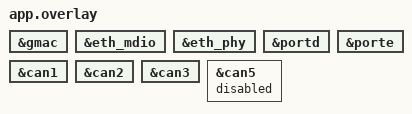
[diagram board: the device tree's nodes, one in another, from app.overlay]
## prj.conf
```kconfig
CONFIG_GPIO=y
CONFIG_PRINTK=y
CONFIG_LOG=y
CONFIG_MAIN_STACK_SIZE=3072

# --- CAN: Robstride motors are classic CAN 2.0B only -----------------------
CONFIG_CAN=y
CONFIG_CAN_FD_MODE=n

# --- Ethernet ----------------------------------------------------------------
# The Ethernet driver does no cache maintenance on packet buffers yet.
CONFIG_DCACHE=n

CONFIG_NETWORKING=y
CONFIG_NET_L2_ETHERNET=y
CONFIG_ETH_DRIVER=y
CONFIG_MDIO=y
CONFIG_NET_IPV4=y
CONFIG_NET_IPV6=n
CONFIG_NET_UDP=y
CONFIG_NET_TCP=n
CONFIG_NET_SOCKETS=y

# Board = 192.168.10.2, Jetson = 192.168.10.1 (udp_protocol/README.md)
CONFIG_NET_CONFIG_SETTINGS=y
CONFIG_NET_CONFIG_NEED_IPV4=y
CONFIG_NET_CONFIG_MY_IPV4_ADDR="192.168.10.2"
CONFIG_NET_CONFIG_MY_IPV4_NETMASK="255.255.255.0"
CONFIG_NET_CONFIG_PEER_IPV4_ADDR="192.168.10.1"
CONFIG_NET_CONFIG_INIT_TIMEOUT=0

# No TRNG driver for this chip in Zephyr yet (ports/IDs only; not crypto).
CONFIG_TEST_RANDOM_GENERATOR=y

# Bench diagnostics on the UART: "net iface", "net stats", "can show can0"
CONFIG_NET_STATISTICS=y
CONFIG_NET_STATISTICS_ETHERNET=y
CONFIG_SHELL=y
CONFIG_NET_SHELL=y
CONFIG_CAN_SHELL=y

CONFIG_NET_LOG=y
CONFIG_ETHERNET_LOG_LEVEL_INF=y
CONFIG_PHY_LOG_LEVEL_INF=y
```

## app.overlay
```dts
/* Gateway: Ethernet (MAC + MDIO + KSZ9031) and the four motor buses. */
#include "../boards/microchip/mega_can/mega_can-gmac.dtsi"

&gmac {
	status = "okay";
};

&eth_mdio {
	status = "okay";
};

&eth_phy {
	status = "okay";
};

&portd {
	status = "okay";
};

&porte {
	status = "okay";
};

/* motors: can0..can3 (classic 1 Mbit/s, from the board) */
&can1 {
	status = "okay";
};

&can2 {
	status = "okay";
};

&can3 {
	status = "okay";
};

/* can5 is only the bring-up loopback partner; not used here */
&can5 {
	status = "disabled";
};
```

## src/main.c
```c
/*
 * Copyright (c) 2026
 * SPDX-License-Identifier: Apache-2.0
 *
 * Mega-CAN gateway firmware: Jetson <-> UDP (protocol v3) <-> 4 Robstride motors.
 *
 * Same rules as udp_protocol/fake_board.py, which the software team codes
 * against:
 *   - one state packet back for every valid command, to the sender
 *   - 50 ms without a valid command -> all motors off, watchdog flag set
 *   - after that (and at boot) MODE_RUN is ignored until one all-OFF packet
 *   - packets with seq <= the last one used are dropped; a watchdog trip
 *     resets that, so a restarted Jetson program (seq back at 1) is accepted
 *   - bad packets set FLAG_BAD_PACKET in the next reply
 *
 * Foot sensors, ToF and power are reported as "no data" until their hardware
 * details are known.
 */

#include <string.h>

#include <zephyr/kernel.h>
#include <zephyr/drivers/gpio.h>
#include <zephyr/logging/log.h>
#include <zephyr/net/socket.h>

#include "motors.h"
#include "proto.h"

LOG_MODULE_REGISTER(gateway, LOG_LEVEL_INF);

#define WATCHDOG_MS       50
#define POLL_MS           5    /* watchdog check resolution */
#define FEEDBACK_WAIT_US  1500 /* a CAN command + reply takes ~0.3 ms */

static const struct gpio_dt_spec led = GPIO_DT_SPEC_GET(DT_ALIAS(led0), gpios);

static struct proto_command cmd;
static struct proto_state st;

static bool armed;
static uint32_t flags;
static uint32_t last_cmd_seq;
static int64_t last_cmd_ms; /* 0 = no command since boot */

static uint32_t now_us(void)
{
	return (uint32_t)k_ticks_to_us_floor64(k_uptime_ticks());
}

static bool header_ok(const struct proto_command *c)
{
	return memcmp(c->hdr.magic, PROTO_MAGIC, 4) == 0 && c->hdr.version == PROTO_VERSION &&
	       c->hdr.type == PROTO_TYPE_COMMAND && c->hdr.count == PROTO_NUM_MOTORS;
}

static bool all_off(const struct proto_command *c)
{
	for (int i = 0; i < PROTO_NUM_MOTORS; i++) {
		if (c->motor[i].mode != PROTO_MODE_OFF) {
			return false;
		}
	}
	return true;
}

static void trip_watchdog(void)
{
	if (armed) {
		LOG_WRN("watchdog: no command for %d ms, motors off", WATCHDOG_MS);
	}
	motors_all_off();
	armed = false;
	flags |= PROTO_FLAG_WATCHDOG_TRIPPED;
	last_cmd_seq = 0; /* accept a restarted client */
}

static void send_state(int sock, const struct sockaddr *to, socklen_t to_len)
{
	static uint32_t state_seq;

	memset(&st, 0, sizeof(st));
	memcpy(st.hdr.magic, PROTO_MAGIC, 4);
	st.hdr.version = PROTO_VERSION;
	st.hdr.type = PROTO_TYPE_STATE;
	st.hdr.count = PROTO_NUM_MOTORS;
	st.hdr.seq = ++state_seq;
	st.hdr.time_us = now_us();
	st.last_cmd_seq = last_cmd_seq;
	st.flags = flags;
	motors_fill_state(st.motor, st.bus);
	/* feet, tof, power: zeros = PROTO_SENSOR_NO_DATA until hardware is known */

	zsock_sendto(sock, &st, sizeof(st), 0, to, to_len);
}

int main(void)
{
	struct sockaddr_in addr = {
		.sin_family = AF_INET,
		.sin_port = htons(PROTO_PORT),
		.sin_addr.s_addr = htonl(INADDR_ANY),
	};
	int64_t last_blink = 0;
	int sock;

	gpio_pin_configure_dt(&led, GPIO_OUTPUT_INACTIVE);
	LOG_INF("Mega-CAN gateway, protocol v%d, UDP port %d", PROTO_VERSION, PROTO_PORT);

	motors_init();

	sock = zsock_socket(AF_INET, SOCK_DGRAM, IPPROTO_UDP);
	if (sock < 0 || zsock_bind(sock, (struct sockaddr *)&addr, sizeof(addr)) < 0) {
		LOG_ERR("UDP socket setup failed: %d", errno);
		return 0;
	}

	while (1) {
		struct zsock_pollfd pfd = {.fd = sock, .events = ZSOCK_POLLIN};
		struct sockaddr_in from;
		socklen_t from_len = sizeof(from);
		int64_t now;
		int len;

		zsock_poll(&pfd, 1, POLL_MS);
		now = k_uptime_get();

		/* LED: slow blink disarmed, fast blink armed */
		if (now - last_blink >= (armed ? 100 : 500)) {
			gpio_pin_toggle_dt(&led);
			last_blink = now;
		}

		if (last_cmd_ms != 0 && now - last_cmd_ms > WATCHDOG_MS &&
		    !(flags & PROTO_FLAG_WATCHDOG_TRIPPED)) {
			trip_watchdog();
		}

		if (!(pfd.revents & ZSOCK_POLLIN)) {
			continue;
		}
		len = zsock_recvfrom(sock, &cmd, sizeof(cmd), ZSOCK_MSG_DONTWAIT,
				     (struct sockaddr *)&from, &from_len);
		if (len < 0) {
			continue;
		}
		if (len != sizeof(cmd) || !header_ok(&cmd)) {
			flags |= PROTO_FLAG_BAD_PACKET;
			continue;
		}
		if (last_cmd_seq != 0 && cmd.hdr.seq <= last_cmd_seq) {
			continue; /* old or duplicate */
		}

		last_cmd_seq = cmd.hdr.seq;
		last_cmd_ms = now;
		if (all_off(&cmd)) {
			if (!armed) {
				LOG_INF("armed (all-off packet received)");
			}
			armed = true;
			flags &= ~PROTO_FLAG_WATCHDOG_TRIPPED;
		}

		motors_apply(cmd.motor, armed);
		motors_wait_feedback(K_USEC(FEEDBACK_WAIT_US));
		send_state(sock, (struct sockaddr *)&from, from_len);
		flags &= ~PROTO_FLAG_BAD_PACKET;
	}
	return 0;
}
```

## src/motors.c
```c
/*
 * Copyright (c) 2026
 * SPDX-License-Identifier: Apache-2.0
 *
 * Robstride motors on can0..can3. See motors.h.
 *
 * Frame per motor per tick (Robstride answers each with type 2 feedback):
 *   OFF       -> stop (type 4). Keeps feedback flowing while off.
 *   RUN       -> first tick: enable (type 3); after that: control (type 1)
 *   SET_ZERO  -> stop until the motor reports it is not running, then one
 *                set-zero (type 6). Never zeroes a running motor: with
 *                position gains active, moving the zero makes it jump.
 */

#include "motors.h"

#include <string.h>

#include <zephyr/device.h>
#include <zephyr/drivers/can.h>
#include <zephyr/logging/log.h>

#include "robstride.h"

LOG_MODULE_REGISTER(motors, LOG_LEVEL_INF);

#define HOST_ID            RS_DEFAULT_HOST_ID
#define MOTOR_CAN_TIMEOUT  100U /* ms: motor resets itself if CAN goes quiet */
#define FEEDBACK_STALE_MS  50
#define INIT_REPLY_TIMEOUT K_MSEC(20)

struct motor {
	const struct device *dev;
	uint8_t bus;
	uint8_t can_id;
	/* tick state (main thread only) */
	bool enabled;
	bool zeroed;
	/* feedback (written in the CAN RX callback) */
	struct rs_feedback fb;
	int64_t fb_time_ms; /* 0 = never */
};

/* Motor i on can<i>, factory ID 0x7F (IDs never changed, per Joa 2026-09-28). */
static struct motor motors[PROTO_NUM_MOTORS] = {
	{.dev = DEVICE_DT_GET(DT_NODELABEL(can0)), .bus = 0, .can_id = RS_DEFAULT_MOTOR_ID},
	{.dev = DEVICE_DT_GET(DT_NODELABEL(can1)), .bus = 1, .can_id = RS_DEFAULT_MOTOR_ID},
	{.dev = DEVICE_DT_GET(DT_NODELABEL(can2)), .bus = 2, .can_id = RS_DEFAULT_MOTOR_ID},
	{.dev = DEVICE_DT_GET(DT_NODELABEL(can3)), .bus = 3, .can_id = RS_DEFAULT_MOTOR_ID},
};

/* Bus health for all six controllers (unused ones report zeros). */
static const struct device *const bus_devs[PROTO_NUM_BUSES] = {
	DEVICE_DT_GET(DT_NODELABEL(can0)), DEVICE_DT_GET(DT_NODELABEL(can1)),
	DEVICE_DT_GET(DT_NODELABEL(can2)), DEVICE_DT_GET(DT_NODELABEL(can3)),
	NULL, NULL,
};

static struct k_spinlock fb_lock;
static atomic_t replied;  /* bit i = motor i answered this tick */
static uint32_t expected; /* bits of motors sent to this tick */
static K_SEM_DEFINE(reply_sem, 0, K_SEM_MAX_LIMIT);

static void rx_cb(const struct device *dev, struct can_frame *frame, void *user_data)
{
	struct motor *m = user_data;
	struct rs_frame rf = {.id = frame->id, .len = frame->dlc};
	struct rs_feedback fb;

	ARG_UNUSED(dev);
	memcpy(rf.data, frame->data, sizeof(rf.data));
	if (rs_parse_feedback(&rf, &fb) != 0 || fb.motor_id != m->can_id) {
		return;
	}

	k_spinlock_key_t key = k_spin_lock(&fb_lock);

	m->fb = fb;
	m->fb_time_ms = k_uptime_get();
	k_spin_unlock(&fb_lock, key);

	atomic_set_bit(&replied, m - motors);
	k_sem_give(&reply_sem);
}

static void tx_done(const struct device *dev, int error, void *user_data)
{
	ARG_UNUSED(dev);
	ARG_UNUSED(error);
	ARG_UNUSED(user_data);
}

static int send(struct motor *m, const struct rs_frame *rf)
{
	struct can_frame f = {
		.id = rf->id,
		.dlc = rf->len,
		.flags = CAN_FRAME_IDE, /* classic 2.0B, 29-bit; never FD */
	};

	memcpy(f.data, rf->data, rf->len);
	/* async: returns once queued, so the four buses go out in parallel */
	return can_send(m->dev, &f, K_MSEC(1), tx_done, NULL);
}

int motors_init(void)
{
	const struct can_filter feedback = {
		.id = HOST_ID, /* type 2 feedback: bits 7..0 = host ID */
		.mask = 0xFF,
		.flags = CAN_FILTER_IDE,
	};
	struct rs_frame rf;

	for (int i = 0; i < PROTO_NUM_MOTORS; i++) {
		struct motor *m = &motors[i];

		if (!device_is_ready(m->dev) || can_set_mode(m->dev, CAN_MODE_NORMAL) != 0 ||
		    can_start(m->dev) != 0) {
			LOG_ERR("can%u failed to start", m->bus);
			m->dev = NULL;
			continue;
		}
		if (can_add_rx_filter(m->dev, rx_cb, m, &feedback) < 0) {
			LOG_ERR("can%u: no RX filter", m->bus);
		}

		/* Motor-side watchdog. Lost at power-off, so set on every boot. */
		rs_build_param_write_u32(&rf, HOST_ID, m->can_id, RS_PARAM_CAN_TIMEOUT,
					 MOTOR_CAN_TIMEOUT * RS_CAN_TIMEOUT_PER_MS);
		atomic_clear(&replied);
		send(m, &rf);
		k_sem_take(&reply_sem, INIT_REPLY_TIMEOUT);
		if (atomic_test_bit(&replied, i)) {
			LOG_INF("motor %d (can%u, id 0x%02x): answered, CAN_TIMEOUT %u ms", i,
				m->bus, m->can_id, MOTOR_CAN_TIMEOUT);
		} else {
			LOG_WRN("motor %d (can%u, id 0x%02x): no answer", i, m->bus, m->can_id);
		}
	}
	return 0;
}

void motors_apply(const struct proto_cmd_motor cmd[PROTO_NUM_MOTORS], bool armed)
{
	struct rs_frame rf;

	atomic_clear(&replied);
	k_sem_reset(&reply_sem);
	expected = 0;

	for (int i = 0; i < PROTO_NUM_MOTORS; i++) {
		struct motor *m = &motors[i];
		uint8_t mode = cmd[i].mode;

		if (m->dev == NULL) {
			continue;
		}
		if (mode == PROTO_MODE_RUN && !armed) {
			mode = PROTO_MODE_OFF;
		}
		if (mode != PROTO_MODE_SET_ZERO) {
			m->zeroed = false;
		}

		switch (mode) {
		case PROTO_MODE_RUN:
			if (!m->enabled) {
				rs_build_enable(&rf, HOST_ID, m->can_id);
				m->enabled = true;
			} else {
				const struct rs_command c = {
					.p = cmd[i].p_des,
					.v = cmd[i].v_des,
					.kp = cmd[i].kp,
					.kd = cmd[i].kd,
					.t_ff = cmd[i].tau_ff,
				};

				rs_build_control(&rf, m->can_id, &c); /* clamps to motor limits */
			}
			break;

		case PROTO_MODE_SET_ZERO: {
			k_spinlock_key_t key = k_spin_lock(&fb_lock);
			bool running = m->fb.mode == RS_MODE_RUN;

			k_spin_unlock(&fb_lock, key);
			if (!m->zeroed && !m->enabled && !running) {
				rs_build_set_zero(&rf, HOST_ID, m->can_id);
				m->zeroed = true;
			} else {
				rs_build_stop(&rf, HOST_ID, m->can_id, false);
				m->enabled = false;
			}
			break;
		}

		case PROTO_MODE_OFF:
		default:
			rs_build_stop(&rf, HOST_ID, m->can_id, false);
			m->enabled = false;
			break;
		}

		if (send(m, &rf) == 0) {
			expected |= BIT(i);
		}
	}
}

void motors_all_off(void)
{
	struct rs_frame rf;

	for (int i = 0; i < PROTO_NUM_MOTORS; i++) {
		struct motor *m = &motors[i];

		if (m->dev == NULL) {
			continue;
		}
		rs_build_stop(&rf, HOST_ID, m->can_id, false);
		send(m, &rf);
		m->enabled = false;
	}
}

void motors_wait_feedback(k_timeout_t timeout)
{
	k_timepoint_t end = sys_timepoint_calc(timeout);

	while (((uint32_t)atomic_get(&replied) & expected) != expected) {
		if (k_sem_take(&reply_sem, sys_timepoint_timeout(end)) != 0) {
			break;
		}
	}
}

static uint8_t bus_state(enum can_state s)
{
	switch (s) {
	case CAN_STATE_ERROR_WARNING:
		return 1;
	case CAN_STATE_ERROR_PASSIVE:
		return 2;
	case CAN_STATE_BUS_OFF:
		return 3;
	default:
		return 0;
	}
}

void motors_fill_state(struct proto_st_motor motor[PROTO_NUM_MOTORS],
		       struct proto_st_bus bus[PROTO_NUM_BUSES])
{
	int64_t now = k_uptime_get();

	for (int i = 0; i < PROTO_NUM_MOTORS; i++) {
		struct motor *m = &motors[i];
		struct proto_st_motor *o = &motor[i];
		k_spinlock_key_t key = k_spin_lock(&fb_lock);
		struct rs_feedback fb = m->fb;
		int64_t t = m->fb_time_ms;

		k_spin_unlock(&fb_lock, key);

		o->bus = m->bus;
		o->can_id = m->can_id;
		o->faults = fb.faults;
		o->position = fb.p;
		o->velocity = fb.v;
		o->torque = fb.t;
		o->temperature_c = fb.temp_c;
		if (m->dev == NULL || t == 0 || now - t > FEEDBACK_STALE_MS) {
			o->status = PROTO_MOTOR_NO_REPLY;
		} else if (fb.faults != 0) {
			o->status = PROTO_MOTOR_FAULT;
		} else if (fb.mode == RS_MODE_RUN) {
			o->status = PROTO_MOTOR_RUNNING;
		} else {
			o->status = PROTO_MOTOR_OFF;
		}
	}

	for (int i = 0; i < PROTO_NUM_BUSES; i++) {
		struct can_bus_err_cnt err = {0};
		enum can_state s = CAN_STATE_STOPPED;

		memset(&bus[i], 0, sizeof(bus[i]));
		if (bus_devs[i] != NULL && can_get_state(bus_devs[i], &s, &err) == 0) {
			bus[i].state = bus_state(s);
			bus[i].tx_err = err.tx_err_cnt;
			bus[i].rx_err = err.rx_err_cnt;
		}
	}
}
```

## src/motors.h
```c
/*
 * Copyright (c) 2026
 * SPDX-License-Identifier: Apache-2.0
 *
 * The four Robstride motors, one per CAN bus (motor i on can<i>).
 * One protocol tick = at most one CAN frame per motor; every frame the motor
 * receives is answered with a type 2 feedback frame, collected here.
 */

#ifndef MEGA_CAN_MOTORS_H_
#define MEGA_CAN_MOTORS_H_

#include <stdbool.h>
#include <zephyr/kernel.h>

#include "proto.h"

/* Start the buses and set each motor's CAN_TIMEOUT (motor-side watchdog). */
int motors_init(void);

/*
 * One tick. cmd[i] is motor i's slot from the command packet. While !armed,
 * MODE_RUN is treated as MODE_OFF.
 */
void motors_apply(const struct proto_cmd_motor cmd[PROTO_NUM_MOTORS], bool armed);

/* Stop every motor (watchdog trip). */
void motors_all_off(void);

/* Wait until every motor sent in the last tick has answered, or timeout. */
void motors_wait_feedback(k_timeout_t timeout);

/* Latest motor feedback and CAN bus health, in protocol form. */
void motors_fill_state(struct proto_st_motor motor[PROTO_NUM_MOTORS],
		       struct proto_st_bus bus[PROTO_NUM_BUSES]);

#endif /* MEGA_CAN_MOTORS_H_ */
```

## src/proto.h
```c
/*
 * Copyright (c) 2026
 * SPDX-License-Identifier: Apache-2.0
 *
 * Jetson <-> Mega-CAN UDP protocol v3: the C side of udp_protocol/protocol.py.
 *
 * protocol.py is the source of truth. Every struct here mirrors one of its
 * struct.Struct formats field for field ('<' = little-endian, no implicit
 * padding: explicit pad bytes only, 'x' in the Python format). The size and
 * offset asserts below repeat protocol.py's asserts, and app/tests/ packs
 * bytes in Python and decodes them here (and back) to prove it.
 *
 * Pure C, no Zephyr, so the PC tests can include it.
 */

#ifndef MEGA_CAN_PROTO_H_
#define MEGA_CAN_PROTO_H_

#include <stddef.h>
#include <stdint.h>

#ifdef __cplusplus
extern "C" {
#endif

#define PROTO_MAGIC   "MCAN"
#define PROTO_VERSION 3
#define PROTO_PORT    5000

#define PROTO_TYPE_COMMAND 1
#define PROTO_TYPE_STATE   2

#define PROTO_NUM_MOTORS 4
#define PROTO_NUM_BUSES  6
#define PROTO_NUM_FEET   4
#define PROTO_NUM_TOF    4

/* Motor modes (command) */
#define PROTO_MODE_OFF      0
#define PROTO_MODE_RUN      1
#define PROTO_MODE_SET_ZERO 2

/* Motor status (state) */
#define PROTO_MOTOR_OFF      0
#define PROTO_MOTOR_RUNNING  1
#define PROTO_MOTOR_FAULT    2
#define PROTO_MOTOR_NO_REPLY 3

/* Sensor status (feet, ToF) */
#define PROTO_SENSOR_NO_DATA 0
#define PROTO_SENSOR_OK      1
#define PROTO_SENSOR_STALE   2
#define PROTO_SENSOR_FAULT   3

/* State flags */
#define PROTO_FLAG_WATCHDOG_TRIPPED (1U << 0)
#define PROTO_FLAG_BAD_PACKET       (1U << 1)

#define PROTO_PACKED __attribute__((packed))

/* HEADER = "<4sBBHII" */
struct PROTO_PACKED proto_header {
	char magic[4];
	uint8_t version;
	uint8_t type;
	uint16_t count; /* = PROTO_NUM_MOTORS */
	uint32_t seq;
	uint32_t time_us;
};

/* CMD_MOTOR = "<B3xfffff" */
struct PROTO_PACKED proto_cmd_motor {
	uint8_t mode;
	uint8_t pad[3];
	float p_des;
	float v_des;
	float kp;
	float kd;
	float tau_ff;
};

struct PROTO_PACKED proto_command {
	struct proto_header hdr;
	struct proto_cmd_motor motor[PROTO_NUM_MOTORS];
};

/* ST_MOTOR = "<BBBBffff" */
struct PROTO_PACKED proto_st_motor {
	uint8_t status;
	uint8_t bus;
	uint8_t can_id;
	uint8_t faults;
	float position;
	float velocity;
	float torque;
	float temperature_c;
};

/* ST_BUS = "<BBBx" */
struct PROTO_PACKED proto_st_bus {
	uint8_t state; /* 0 ok, 1 warning, 2 error-passive, 3 bus-off */
	uint8_t tx_err;
	uint8_t rx_err;
	uint8_t pad;
};

/* ST_FOOT = "<BxHfI" */
struct PROTO_PACKED proto_st_foot {
	uint8_t status;
	uint8_t pad;
	uint16_t age_ms;
	float force_n;
	uint32_t raw;
};

/* ST_TOF = "<BxHffff" */
struct PROTO_PACKED proto_st_tof {
	uint8_t status;
	uint8_t pad;
	uint16_t age_ms;
	float distance_m;
	float mag_ut[3];
};

/* ST_POWER = "<ffI" */
struct PROTO_PACKED proto_st_power {
	float bus_voltage_v;
	float bus_current_a;
	uint32_t pgood;
};

struct PROTO_PACKED proto_state {
	struct proto_header hdr;
	uint32_t last_cmd_seq; /* ST_EXTRA = "<II" */
	uint32_t flags;
	struct proto_st_motor motor[PROTO_NUM_MOTORS];
	struct proto_st_bus bus[PROTO_NUM_BUSES];
	struct proto_st_foot foot[PROTO_NUM_FEET];
	struct proto_st_tof tof[PROTO_NUM_TOF];
	struct proto_st_power power;
};

/* protocol.py: assert COMMAND_SIZE == 112, STATE_SIZE == 268 */
_Static_assert(sizeof(struct proto_header) == 16, "HEADER");
_Static_assert(sizeof(struct proto_cmd_motor) == 24, "CMD_MOTOR");
_Static_assert(sizeof(struct proto_command) == 112, "COMMAND_SIZE");
_Static_assert(sizeof(struct proto_st_motor) == 20, "ST_MOTOR");
_Static_assert(sizeof(struct proto_st_bus) == 4, "ST_BUS");
_Static_assert(sizeof(struct proto_st_foot) == 12, "ST_FOOT");
_Static_assert(sizeof(struct proto_st_tof) == 20, "ST_TOF");
_Static_assert(sizeof(struct proto_st_power) == 12, "ST_POWER");
_Static_assert(sizeof(struct proto_state) == 268, "STATE_SIZE");
/* block offsets from udp_protocol/README.md */
_Static_assert(offsetof(struct proto_state, motor) == 24, "motors @24");
_Static_assert(offsetof(struct proto_state, bus) == 104, "buses @104");
_Static_assert(offsetof(struct proto_state, foot) == 128, "feet @128");
_Static_assert(offsetof(struct proto_state, tof) == 176, "tof @176");
_Static_assert(offsetof(struct proto_state, power) == 256, "power @256");
_Static_assert(sizeof(float) == 4, "IEEE-754 single");
_Static_assert(__BYTE_ORDER__ == __ORDER_LITTLE_ENDIAN__, "protocol is little-endian");

#ifdef __cplusplus
}
#endif

#endif /* MEGA_CAN_PROTO_H_ */
```

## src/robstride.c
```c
/*
 * Copyright (c) 2026
 * SPDX-License-Identifier: Apache-2.0
 *
 * Robstride 02 private-protocol frames. See robstride.h for the frame layout.
 */

#include "robstride.h"

#include <string.h>

#define RS_ID_TYPE_SHIFT  24
#define RS_ID_AREA2_SHIFT 8
#define RS_ID_TYPE_MASK   0x1FU
#define RS_ID_AREA2_MASK  0xFFFFU
#define RS_ID_TARGET_MASK 0xFFU

static uint32_t rs_id(uint8_t type, uint16_t area2, uint8_t target)
{
	return ((uint32_t)(type & RS_ID_TYPE_MASK) << RS_ID_TYPE_SHIFT) |
	       ((uint32_t)area2 << RS_ID_AREA2_SHIFT) | target;
}

static void rs_frame_init(struct rs_frame *f, uint8_t type, uint16_t area2, uint8_t target)
{
	f->id = rs_id(type, area2, target);
	f->len = 8;
	memset(f->data, 0, sizeof(f->data));
}

static void put_be16(uint8_t *p, uint16_t v)
{
	p[0] = (uint8_t)(v >> 8);
	p[1] = (uint8_t)v;
}

static uint16_t get_be16(const uint8_t *p)
{
	return (uint16_t)((p[0] << 8) | p[1]);
}

static void put_le16(uint8_t *p, uint16_t v)
{
	p[0] = (uint8_t)v;
	p[1] = (uint8_t)(v >> 8);
}

static void put_le32(uint8_t *p, uint32_t v)
{
	for (int i = 0; i < 4; i++) {
		p[i] = (uint8_t)(v >> (8 * i));
	}
}

static uint32_t get_le32(const uint8_t *p)
{
	return (uint32_t)p[0] | ((uint32_t)p[1] << 8) | ((uint32_t)p[2] << 16) |
	       ((uint32_t)p[3] << 24);
}

uint8_t rs_frame_type(uint32_t id)
{
	return (uint8_t)((id >> RS_ID_TYPE_SHIFT) & RS_ID_TYPE_MASK);
}

/*
 * The protocol maps [min, max] linearly onto 0..65535 (manual 4.1.2).
 * Rounded to the nearest step; out-of-range inputs (NaN included) clamp.
 */
uint16_t rs_float_to_u16(float x, float min, float max)
{
	if (!(x > min)) { /* also catches NaN */
		return 0;
	}
	if (x >= max) {
		return 65535;
	}
	return (uint16_t)((x - min) * 65535.0f / (max - min) + 0.5f);
}

float rs_u16_to_float(uint16_t u, float min, float max)
{
	return min + (float)u * (max - min) / 65535.0f;
}

void rs_build_control(struct rs_frame *f, uint8_t motor_id, const struct rs_command *cmd)
{
	uint16_t torque = rs_float_to_u16(cmd->t_ff, -RS_T_MAX, RS_T_MAX);

	rs_frame_init(f, RS_TYPE_CONTROL, torque, motor_id);
	put_be16(&f->data[0], rs_float_to_u16(cmd->p, -RS_P_MAX, RS_P_MAX));
	put_be16(&f->data[2], rs_float_to_u16(cmd->v, -RS_V_MAX, RS_V_MAX));
	put_be16(&f->data[4], rs_float_to_u16(cmd->kp, 0.0f, RS_KP_MAX));
	put_be16(&f->data[6], rs_float_to_u16(cmd->kd, 0.0f, RS_KD_MAX));
}

void rs_build_enable(struct rs_frame *f, uint8_t host_id, uint8_t motor_id)
{
	rs_frame_init(f, RS_TYPE_ENABLE, host_id, motor_id);
}

void rs_build_stop(struct rs_frame *f, uint8_t host_id, uint8_t motor_id, bool clear_faults)
{
	rs_frame_init(f, RS_TYPE_STOP, host_id, motor_id);
	f->data[0] = clear_faults ? 1U : 0U;
}

void rs_build_set_zero(struct rs_frame *f, uint8_t host_id, uint8_t motor_id)
{
	rs_frame_init(f, RS_TYPE_SET_ZERO, host_id, motor_id);
	f->data[0] = 1U;
}

void rs_build_get_id(struct rs_frame *f, uint8_t host_id, uint8_t motor_id)
{
	rs_frame_init(f, RS_TYPE_GET_ID, host_id, motor_id);
}

void rs_build_param_read(struct rs_frame *f, uint8_t host_id, uint8_t motor_id, uint16_t index)
{
	rs_frame_init(f, RS_TYPE_PARAM_READ, host_id, motor_id);
	put_le16(&f->data[0], index);
}

void rs_build_param_write_u32(struct rs_frame *f, uint8_t host_id, uint8_t motor_id,
			      uint16_t index, uint32_t value)
{
	rs_frame_init(f, RS_TYPE_PARAM_WRITE, host_id, motor_id);
	put_le16(&f->data[0], index);
	put_le32(&f->data[4], value);
}

void rs_build_param_write_float(struct rs_frame *f, uint8_t host_id, uint8_t motor_id,
				uint16_t index, float value)
{
	uint32_t raw;

	memcpy(&raw, &value, sizeof(raw)); /* IEEE-754 bits, sent little-endian */
	rs_build_param_write_u32(f, host_id, motor_id, index, raw);
}

int rs_parse_feedback(const struct rs_frame *f, struct rs_feedback *out)
{
	uint16_t area2 = (uint16_t)((f->id >> RS_ID_AREA2_SHIFT) & RS_ID_AREA2_MASK);

	if (rs_frame_type(f->id) != RS_TYPE_FEEDBACK || f->len < 8) {
		return -1;
	}

	/* data area 2: bits 8..15 motor ID, 16..21 faults, 22..23 mode */
	out->motor_id = (uint8_t)area2;
	out->faults = (uint8_t)((area2 >> 8) & 0x3FU);
	out->mode = (uint8_t)((area2 >> 14) & 0x3U);
	out->host_id = (uint8_t)(f->id & RS_ID_TARGET_MASK);

	out->p = rs_u16_to_float(get_be16(&f->data[0]), -RS_P_MAX, RS_P_MAX);
	out->v = rs_u16_to_float(get_be16(&f->data[2]), -RS_V_MAX, RS_V_MAX);
	out->t = rs_u16_to_float(get_be16(&f->data[4]), -RS_T_MAX, RS_T_MAX);
	out->temp_c = (float)(int16_t)get_be16(&f->data[6]) / 10.0f;
	return 0;
}

int rs_parse_param_reply(const struct rs_frame *f, uint8_t *motor_id, uint16_t *index,
			 uint32_t *raw_value)
{
	if (rs_frame_type(f->id) != RS_TYPE_PARAM_READ || f->len < 8) {
		return -1;
	}

	/* reply: bits 15..8 = motor ID, bits 7..0 = host ID (manual 4.1.15) */
	*motor_id = (uint8_t)(f->id >> RS_ID_AREA2_SHIFT);
	*index = (uint16_t)(f->data[0] | (f->data[1] << 8));
	*raw_value = get_le32(&f->data[4]);
	return 0;
}
```

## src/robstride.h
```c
/*
 * Copyright (c) 2026
 * SPDX-License-Identifier: Apache-2.0
 *
 * Robstride 02 "private protocol" frames (ROBSTRIDE 02 user manual, section 4).
 *
 * Pure C, no Zephyr: builds on a PC for the unit tests in ../tests/. The
 * firmware copies rs_frame into a Zephyr struct can_frame with the extended
 * ID flag set (CAN_FRAME_IDE) and no FD flags: classic CAN 2.0B, 1 Mbit/s.
 *
 * Every frame has a 29-bit extended ID in three parts, plus 8 data bytes:
 *
 *   bits 28..24   bits 23..8           bits 7..0
 *   [ type ]      [ data area 2 ]      [ target ID ]
 *
 * For most board->motor frames, data area 2 carries the host (board) CAN ID in
 * bits 15..8. Control frames (type 1) put the torque there instead.
 *
 * Byte order is NOT uniform (both from the manual):
 *   - control (1) and feedback (2) values: 16-bit, BIG-endian
 *   - parameter read/write (17/18): index and value LITTLE-endian
 */

#ifndef MEGA_CAN_ROBSTRIDE_H_
#define MEGA_CAN_ROBSTRIDE_H_

#include <stdbool.h>
#include <stdint.h>

#ifdef __cplusplus
extern "C" {
#endif

/* Communication types (manual 4.1) */
enum rs_type {
	RS_TYPE_GET_ID = 0,
	RS_TYPE_CONTROL = 1,
	RS_TYPE_FEEDBACK = 2,
	RS_TYPE_ENABLE = 3,
	RS_TYPE_STOP = 4,
	RS_TYPE_SET_ZERO = 6,
	RS_TYPE_SET_CAN_ID = 7,
	RS_TYPE_PARAM_READ = 17,
	RS_TYPE_PARAM_WRITE = 18,
	RS_TYPE_FAULT = 21,
};

/* Control ranges (manual 4.1.2; P_MAX per 4.2.3 is 12.57 = 4*pi) */
#define RS_P_MAX  12.566370614f /* rad */
#define RS_V_MAX  44.0f         /* rad/s */
#define RS_KP_MAX 500.0f
#define RS_KD_MAX 5.0f
#define RS_T_MAX  17.0f         /* N*m */

/* Factory defaults seen in the manual's examples */
#define RS_DEFAULT_MOTOR_ID 0x7F
#define RS_DEFAULT_HOST_ID  0xFD

/* Parameters (manual 3.3 table) */
#define RS_PARAM_CAN_TIMEOUT 0x200C /* uint32, 20000 = 1 s (50 us units), 0 = off */
#define RS_CAN_TIMEOUT_PER_MS 20U

/* Feedback fault bits (type 2 ID bits 16..21, shifted down to bit 0).
 * Same order as FAULT_* in udp_protocol/protocol.py. */
#define BIT_U8(n)             ((uint8_t)(1U << (n)))
#define RS_FAULT_UNDERVOLTAGE BIT_U8(0)
#define RS_FAULT_OVERCURRENT  BIT_U8(1)
#define RS_FAULT_OVERTEMP     BIT_U8(2)
#define RS_FAULT_ENCODER      BIT_U8(3)
#define RS_FAULT_OVERLOAD     BIT_U8(4)
#define RS_FAULT_UNCALIBRATED BIT_U8(5)

/* Mode reported in feedback (type 2 ID bits 22..23) */
enum rs_mode {
	RS_MODE_RESET = 0,
	RS_MODE_CALIBRATION = 1,
	RS_MODE_RUN = 2,
};

/* One classic CAN frame: 29-bit extended ID + up to 8 bytes. */
struct rs_frame {
	uint32_t id;
	uint8_t len;
	uint8_t data[8];
};

/* Operation-control command: t = kp*(p - p_act) + kd*(v - v_act) + t_ff */
struct rs_command {
	float p;    /* target position, rad */
	float v;    /* target velocity, rad/s */
	float kp;
	float kd;
	float t_ff; /* feed-forward torque, N*m */
};

struct rs_feedback {
	uint8_t motor_id;
	uint8_t host_id;
	uint8_t faults; /* RS_FAULT_* */
	uint8_t mode;   /* enum rs_mode */
	float p;        /* rad */
	float v;        /* rad/s */
	float t;        /* N*m */
	float temp_c;   /* winding temperature, deg C */
};

/* Frame type (bits 28..24) of any Robstride ID. */
uint8_t rs_frame_type(uint32_t id);

/* Board -> motor. Values outside the ranges above are clamped. */
void rs_build_control(struct rs_frame *f, uint8_t motor_id, const struct rs_command *cmd);
void rs_build_enable(struct rs_frame *f, uint8_t host_id, uint8_t motor_id);
void rs_build_stop(struct rs_frame *f, uint8_t host_id, uint8_t motor_id, bool clear_faults);
void rs_build_set_zero(struct rs_frame *f, uint8_t host_id, uint8_t motor_id);
void rs_build_get_id(struct rs_frame *f, uint8_t host_id, uint8_t motor_id);
void rs_build_param_read(struct rs_frame *f, uint8_t host_id, uint8_t motor_id, uint16_t index);
void rs_build_param_write_u32(struct rs_frame *f, uint8_t host_id, uint8_t motor_id,
			      uint16_t index, uint32_t value);
void rs_build_param_write_float(struct rs_frame *f, uint8_t host_id, uint8_t motor_id,
				uint16_t index, float value);

/* Motor -> board. Return 0 on success, -1 if the frame isn't that type. */
int rs_parse_feedback(const struct rs_frame *f, struct rs_feedback *out);
int rs_parse_param_reply(const struct rs_frame *f, uint8_t *motor_id, uint16_t *index,
			 uint32_t *raw_value);

/* The 16-bit scaling the protocol uses, exposed for tests. */
uint16_t rs_float_to_u16(float x, float min, float max);
float rs_u16_to_float(uint16_t u, float min, float max);

#ifdef __cplusplus
}
#endif

#endif /* MEGA_CAN_ROBSTRIDE_H_ */
```
